AUTOSAR XML (schema 4-3-0)
package /BMW/Platform/Bs/SwComponentTypes
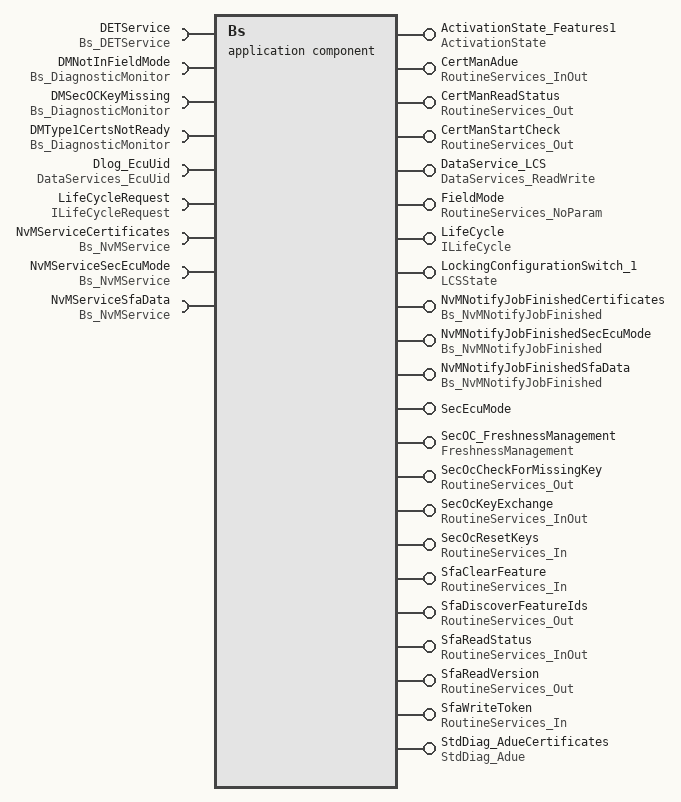
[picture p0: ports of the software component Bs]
  application sw component type Bs
    4 x provide port:
      ActivationState_Features1: provided-interface=ActivationState
      CertManAdue: provided-interface=RoutineServices_InOut
      CertManReadStatus: provided-interface=RoutineServices_Out
      CertManStartCheck: provided-interface=RoutineServices_Out
    4 x require port:
      DETService: required-interface=Bs_DETService
      DMNotInFieldMode: required-interface=Bs_DiagnosticMonitor
      DMSecOCKeyMissing: required-interface=Bs_DiagnosticMonitor
      DMType1CertsNotReady: required-interface=Bs_DiagnosticMonitor
    provide port DataService_LCS: provided-interface=DataServices_ReadWrite
    require port Dlog_EcuUid: required-interface=DataServices_EcuUid
    provide port FieldMode: provided-interface=RoutineServices_NoParam
    provide port LifeCycle: mode-switch-sender-com-spec{enhanced-mode-api=true, mode-group=Mode, queue-length=2}, provided-interface=ILifeCycle
    require port LifeCycleRequest: nonqueued-receiver-com-spec{data-element=requestMode, init-value=2}, required-interface=ILifeCycleRequest
    4 x provide port:
      LockingConfigurationSwitch_1: provided-interface=LCSState
      NvMNotifyJobFinishedCertificates: provided-interface=Bs_NvMNotifyJobFinished
      NvMNotifyJobFinishedSecEcuMode: provided-interface=Bs_NvMNotifyJobFinished
      NvMNotifyJobFinishedSfaData: provided-interface=Bs_NvMNotifyJobFinished
    require port NvMServiceCertificates: required-interface=Bs_NvMService
    require port NvMServiceSecEcuMode: required-interface=Bs_NvMService
    require port NvMServiceSfaData: required-interface=Bs_NvMService
    11 x provide port:
      SecEcuMode: provided-interface=SecEcuMode
      SecOC_FreshnessManagement: provided-interface=FreshnessManagement
      SecOcCheckForMissingKey: provided-interface=RoutineServices_Out
      SecOcKeyExchange: provided-interface=RoutineServices_InOut
      SecOcResetKeys: provided-interface=RoutineServices_In
      SfaClearFeature: provided-interface=RoutineServices_In
      SfaDiscoverFeatureIds: provided-interface=RoutineServices_Out
      SfaReadStatus: provided-interface=RoutineServices_InOut
      SfaReadVersion: provided-interface=RoutineServices_Out
      SfaWriteToken: provided-interface=RoutineServices_In
      StdDiag_AdueCertificates: provided-interface=StdDiag_Adue
    behavior Bs_IB: data-type-mapping=BsTypeMappings, handle-termination-and-restart=NO-SUPPORT, port-api-option{enable-take-address=true, error-handling=NO-TRANSFORMER-ERROR-HANDLING, indirect-api=false, port=ActivationState_Features1}
      data received event dre_LifeCycleRequest: start-on-event=Bs_LifeCycleModeRequest, data=LifeCycleRequest.requestMode
      33 x operation invoked event:
        oie_CertManAdue_Start: start-on-event=Bs_UDSRoutineControlStartCertManAdue, operation=CertManAdue.Start
        oie_CertManReadStatus_Start: start-on-event=Bs_UDSRoutineControlStartCertManReadStatus, operation=CertManReadStatus.Start
        oie_CertManStartCheck_Start: start-on-event=Bs_UDSRoutineControlStartCertManStartCheck, operation=CertManStartCheck.Start
        oie_DataService_LCS_ConditionCheckRead: start-on-event=Bs_UDSConditionCheckReadLCS, operation=DataService_LCS.ConditionCheckRead
        oie_DataService_LCS_ReadData: start-on-event=Bs_UDSReadDataByIdentifierLCS, operation=DataService_LCS.ReadData
        oie_DataService_LCS_ReadDataLength: start-on-event=Bs_UDSReadDataLengthLCS, operation=DataService_LCS.ReadDataLength
        oie_DataService_LCS_WriteData: start-on-event=Bs_UDSWriteDataByIdentifierLCS, operation=DataService_LCS.WriteData
        oie_FieldMode_Start: start-on-event=Bs_UDSRoutineControlStartFieldMode, operation=FieldMode.Start
        oie_NvMNotifyJobFinishedCertificates_JobFinished: start-on-event=Bs_NvMNotifyJobFinishedCertificates, operation=NvMNotifyJobFinishedCertificates.JobFinished
        oie_NvMNotifyJobFinishedSecEcuMode_JobFinished: start-on-event=Bs_NvMNotifyJobFinishedSecEcuMode, operation=NvMNotifyJobFinishedSecEcuMode.JobFinished
        oie_NvMNotifyJobFinishedSfaData_JobFinished: start-on-event=Bs_NvMNotifyJobFinishedSfaData, operation=NvMNotifyJobFinishedSfaData.JobFinished
        oie_SecOC_FreshnessManagement_GetRxFreshnessAuthData: start-on-event=Bs_SecOCFMGetRxFreshnessAuthData, operation=SecOC_FreshnessManagement.GetRxFreshnessAuthData
        oie_SecOC_FreshnessManagement_GetTxFreshnessTruncData: start-on-event=Bs_SecOCFMGetTxFreshnessTruncData, operation=SecOC_FreshnessManagement.GetTxFreshnessTruncData
        oie_SecOC_FreshnessManagement_SPduTxConfirmation: start-on-event=Bs_SecOCFMSPduTxConfirmation, operation=SecOC_FreshnessManagement.SPduTxConfirmation
        oie_SecOcCheckForMissingKey_Start: start-on-event=Bs_UDSRoutineControlStartSecOcCheckForMissingKey, operation=SecOcCheckForMissingKey.Start
        oie_SecOcKeyExchange_Start: start-on-event=Bs_UDSRoutineControlStartSecOcKeyExchange, operation=SecOcKeyExchange.Start
        oie_SecOcResetKeys_Start: start-on-event=Bs_UDSRoutineControlStartSecOcResetKeys, operation=SecOcResetKeys.Start
        oie_SfaClearFeature_Start: start-on-event=Bs_UDSRoutineControlStartSfaClearFeature, operation=SfaClearFeature.Start
        oie_SfaDiscoverFeatureIds_Start: start-on-event=Bs_UDSRoutineControlStartSfaDiscoverFeatureIds, operation=SfaDiscoverFeatureIds.Start
        oie_SfaReadStatus_Start: start-on-event=Bs_UDSRoutineControlStartSfaReadStatus, operation=SfaReadStatus.Start
        oie_SfaReadVersion_Start: start-on-event=Bs_UDSRoutineControlStartSfaReadVersion, operation=SfaReadVersion.Start
        oie_SfaWriteToken_Start: start-on-event=Bs_UDSRoutineControlStartSfaWriteToken, operation=SfaWriteToken.Start
        oie_StdDiag_AdueCertificates_CancelOperation: start-on-event=Bs_AdueCertificatesCancel, operation=StdDiag_AdueCertificates.CancelOperation
        oie_StdDiag_AdueCertificates_Download: start-on-event=Bs_AdueCertificatesDownload, operation=StdDiag_AdueCertificates.Download
        oie_StdDiag_AdueCertificates_DownloadPostprocess: start-on-event=Bs_AdueCertificatesDownloadPostprocess, operation=StdDiag_AdueCertificates.DownloadPostprocess
        oie_StdDiag_AdueCertificates_DownloadPreprocess: start-on-event=Bs_AdueCertificatesDownloadPreprocess, operation=StdDiag_AdueCertificates.DownloadPreprocess
        oie_StdDiag_AdueCertificates_ReqeuestDownload: start-on-event=Bs_AdueCertificatesReqeuestDownload, operation=StdDiag_AdueCertificates.RequestDownload
        oie_StdDiag_AdueCertificates_RequestDownloadExit: start-on-event=Bs_AdueCertificatesRequestDownloadExit, operation=StdDiag_AdueCertificates.RequestDownloadExit
        oie_StdDiag_AdueCertificates_RequestUpload: start-on-event=Bs_AdueCertificatesRequestUpload, operation=StdDiag_AdueCertificates.RequestUpload
        oie_StdDiag_AdueCertificates_RequestUploadExit: start-on-event=Bs_AdueCertificatesRequestUploadExit, operation=StdDiag_AdueCertificates.RequestUploadExit
        oie_StdDiag_AdueCertificates_Upload: start-on-event=Bs_AdueCertificatesUpload, operation=StdDiag_AdueCertificates.Upload
        oie_StdDiag_AdueCertificates_UploadPostprocess: start-on-event=Bs_AdueCertificatesUploadPostprocess, operation=StdDiag_AdueCertificates.UploadPostprocess
        oie_StdDiag_AdueCertificates_UploadPreprocess: start-on-event=Bs_AdueCertificatesUploadPreprocess, operation=StdDiag_AdueCertificates.UploadPreprocess
      34 x runnable:
        Bs_AdueCertificatesCancel
        Bs_AdueCertificatesDownload
        Bs_AdueCertificatesDownloadPostprocess
        Bs_AdueCertificatesDownloadPreprocess
        Bs_AdueCertificatesReqeuestDownload: symbol=Bs_AdueCertificates_ReqeuestDownload
        Bs_AdueCertificatesRequestDownloadExit
        Bs_AdueCertificatesRequestUpload
        Bs_AdueCertificatesRequestUploadExit
        Bs_AdueCertificatesUpload
        Bs_AdueCertificatesUploadPostprocess
        Bs_AdueCertificatesUploadPreprocess
          sync call scp_ReportError: operation=DETService.ReportError, timeout=0.0
        Bs_LifeCycleModeRequest: mode-access-point=LifeCycle.Mode
          data-read-access:
            access dra_requestMode: accessed-variable=LifeCycleRequest.requestMode
          mode switch point msp_proto_Bs_LifeCycle_0: mode-group=LifeCycle.Mode
          mode switch point msp_proto_SecEcuModeGroup_0: mode-group=SecEcuMode.Mode
          sync call scp_GetErrorStatus: operation=NvMServiceSecEcuMode.GetErrorStatus, timeout=0.0
          sync call scp_SetEventStatus: operation=DMNotInFieldMode.SetEventStatus, timeout=0.0
        Bs_NvMNotifyJobFinishedCertificates
        Bs_NvMNotifyJobFinishedSecEcuMode
        Bs_NvMNotifyJobFinishedSfaData
          data-send-points:
            access dsp_IsActivated: accessed-variable=ActivationState_Features1.IsActivated
          mode switch point msp_Mode_0: mode-group=SecEcuMode.Mode
          sync call scp_SetRamBlockStatus: operation=NvMServiceSecEcuMode.SetRamBlockStatus, timeout=0.0
        Bs_SecOCFMGetRxFreshnessAuthData
        Bs_SecOCFMGetTxFreshnessTruncData
        Bs_SecOCFMSPduTxConfirmation
        Bs_UDSConditionCheckReadLCS
        Bs_UDSReadDataByIdentifierLCS
        Bs_UDSReadDataLengthLCS
        Bs_UDSRoutineControlStartCertManAdue
        Bs_UDSRoutineControlStartCertManReadStatus
        Bs_UDSRoutineControlStartCertManStartCheck
        Bs_UDSRoutineControlStartFieldMode
          mode switch point msp_proto_SecEcuModeGroup_1: mode-group=SecEcuMode.Mode
          sync call scp_WriteBlock: operation=NvMServiceSecEcuMode.WriteBlock, timeout=0.0
        Bs_UDSRoutineControlStartSecOcCheckForMissingKey
        Bs_UDSRoutineControlStartSecOcKeyExchange
        Bs_UDSRoutineControlStartSecOcResetKeys
        Bs_UDSRoutineControlStartSfaClearFeature
        Bs_UDSRoutineControlStartSfaDiscoverFeatureIds
        Bs_UDSRoutineControlStartSfaReadStatus
        Bs_UDSRoutineControlStartSfaReadVersion
        Bs_UDSRoutineControlStartSfaWriteToken
          sync call scp_WriteBlock: operation=NvMServiceSecEcuMode.WriteBlock, timeout=0.0
          sync call scp_WriteBlock1: operation=NvMServiceSfaData.WriteBlock, timeout=0.0
          sync call scp_ReadData: operation=Dlog_EcuUid.ReadData, timeout=0.0
        Bs_UDSWriteDataByIdentifierLCS
      swc service dependency NvMCertificates
        assigned-ports:
          port-prototype=NvMServiceCertificates, role=NvMService
          port-prototype=NvMNotifyJobFinishedCertificates, role=NvMNotifyJobFinished
        service-needs:
          nv block needs NvMCertificates: restore-at-start=false, store-at-shutdown=false
      swc service dependency NvMSecEcuMode
        assigned-ports:
          port-prototype=NvMServiceSecEcuMode, role=NvMService
          port-prototype=NvMNotifyJobFinishedSecEcuMode, role=NvMNotifyJobFinished
        service-needs:
          nv block needs NvMSecEcuMode: restore-at-start=true, store-at-shutdown=false
      swc service dependency NvMSfaData
        assigned-ports:
          port-prototype=NvMServiceSfaData, role=NvMService
          port-prototype=NvMNotifyJobFinishedSfaData, role=NvMNotifyJobFinished
        service-needs:
          nv block needs NvMSfaData: restore-at-start=false, store-at-shutdown=false
package /BMW/Platform/Bs/SwcImplementations
  swc implementation Bs_Impl: programming-language=C, sw-version=5.3.0, vendor-id=5, behavior=Bs_IB
    code-descriptors:
      code Bs_Impl_Code: artifact-descriptors=autosar-engineering-object={short-label=Bs_Impl_Code_CodeDesc, category=SWSRC}
    resource consumption Bs
